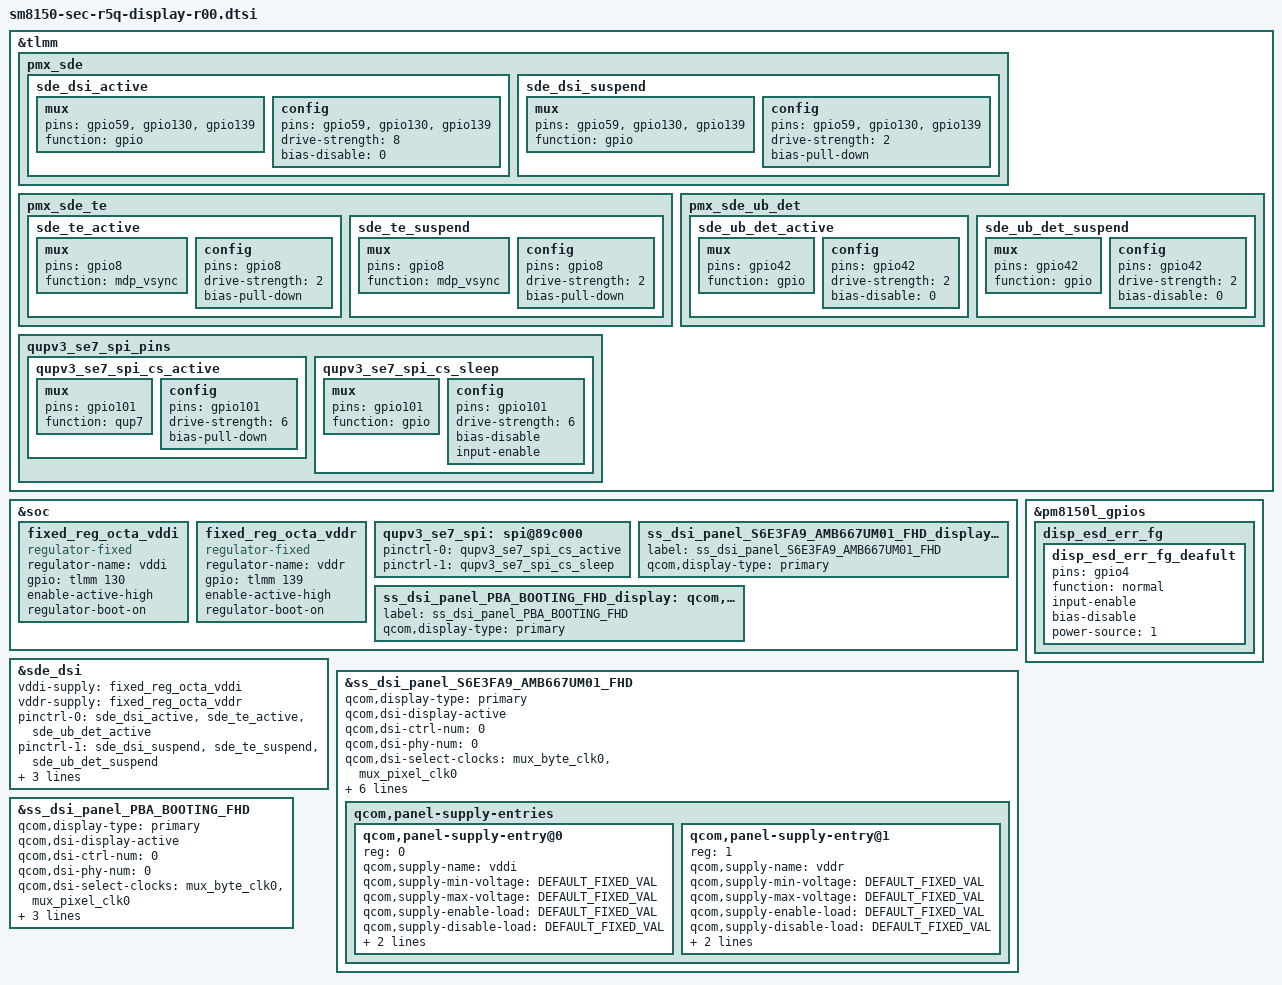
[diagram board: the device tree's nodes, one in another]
/* Copyright (c) 2016-2019, The Linux Foundation. All rights reserved.
 *
 * This program is free software; you can redistribute it and/or modify
 * it under the terms of the GNU General Public License version 2 and
 * only version 2 as published by the Free Software Foundation.
 *
 * This program is distributed in the hope that it will be useful,
 * but WITHOUT ANY WARRANTY; without even the implied warranty of
 * MERCHANTABILITY or FITNESS FOR A PARTICULAR PURPOSE.  See the
 * GNU General Public License for more details.
 */

#include "../../../../../drivers/gpu/drm/msm/samsung/SELF_DISPLAY/self_display_cmd_FA9.dtsi"
#include "../../../../../drivers/gpu/drm/msm/samsung/S6E3FA9_AMB667UM01/dsi_panel_S6E3FA9_AMB667UM01_fhd_octa_cmd.dtsi"
#include "../../../../../drivers/gpu/drm/msm/samsung/PBA_BOOTING/dsi_panel_PBA_BOOTING_fhd_video.dtsi"

#define DEFAULT_FIXED_VAL	0

&tlmm {
	pmx_sde: pmx_sde {
		sde_dsi_active: sde_dsi_active {
			mux {
				pins = "gpio59","gpio130","gpio139";
				function = "gpio";
			};

			config {
				pins = "gpio59","gpio130","gpio139";
				drive-strength = <8>;   /* 8 mA */
				bias-disable = <0>;   /* no pull */
			};
		};
		sde_dsi_suspend: sde_dsi_suspend {
			mux {
				pins = "gpio59","gpio130","gpio139";
				function = "gpio";
			};

			config {
				pins = "gpio59","gpio130","gpio139";
				drive-strength = <2>;   /* 2 mA */
				bias-pull-down;         /* PULL DOWN */
			};
		};
	};

	pmx_sde_te {
		sde_te_active: sde_te_active {
			mux {
				pins = "gpio8";
				function = "mdp_vsync";
			};

			config {
				pins = "gpio8";
				drive-strength = <2>;   /* 2 mA */
				bias-pull-down;         /* PULL DOWN */
			};
		};

		sde_te_suspend: sde_te_suspend {
			mux {
				pins = "gpio8";
				function = "mdp_vsync";
			};

			config {
				pins = "gpio8";
				drive-strength = <2>;   /* 2 mA */
				bias-pull-down;         /* PULL DOWN */
			};
		};
	};

	pmx_sde_ub_det {
		sde_ub_det_active: sde_ub_det_active {	/* UB_CON_DET */
			mux {
				pins = "gpio42";
				function = "gpio";
			};

			config {
				pins = "gpio42";
				drive-strength = <2>;   /* 2 mA */
				bias-disable = <0>;   /* no pull */
			};
		};

		sde_ub_det_suspend: sde_ub_det_suspend {
			mux {
				pins = "gpio42";
				function = "gpio";
			};

			config {
				pins = "gpio42";
				drive-strength = <2>;   /* 2 mA */
				bias-disable = <0>;   /* no pull */
			};
		};
	};

	qupv3_se7_spi_pins: qupv3_se7_spi_pins {
		qupv3_se7_spi_cs_active: qupv3_se7_spi_cs_active {
			mux {
				pins = "gpio101";
				function = "qup7";
			};

			config {
				pins = "gpio101";
				drive-strength = <6>;
				bias-pull-down; /* prevent MISO floating */
			};
		};

		qupv3_se7_spi_cs_sleep: qupv3_se7_spi_cs_sleep {
			mux {
				pins = "gpio101";
				function = "gpio";
			};

			config {
				pins = "gpio101";
				drive-strength = <6>;
				bias-disable;           /* NO PULL */
				input-enable;
			};
		};
	};
};

&soc {
	fixed_reg_octa_vddi: fixed_reg_octa_vddi {
		compatible = "regulator-fixed";
		status = "okay";
		regulator-name = "vddi";
		gpio = <&tlmm 130 0>; /* LCD_LDO_EN : 3.0 & 1.8 V */
		enable-active-high;
		regulator-boot-on;
	};
};

&soc {
	fixed_reg_octa_vddr: fixed_reg_octa_vddr {
		compatible = "regulator-fixed";
		status = "okay";
		regulator-name = "vddr";
		gpio = <&tlmm 139 0>; /* LCD_VDDR_EN : 1.5 V */
		enable-active-high;
		regulator-boot-on;
	};
};

&pm8150l_gpios {
	disp_esd_err_fg {
		disp_esd_err_fg_deafult: disp_esd_err_fg_deafult { // FG_ERR
			pins = "gpio4";
			function = "normal";
			input-enable;
			bias-disable;
			power-source = <1>;
		};
	};
};

&soc {
	qupv3_se7_spi: spi@89c000 {
		status = "ok";

		pinctrl-0 = <&qupv3_se7_spi_cs_active>;
		pinctrl-1 = <&qupv3_se7_spi_cs_sleep>;
	};
};

&soc {
	/* R5 Panel */
	ss_dsi_panel_S6E3FA9_AMB667UM01_FHD_display: qcom,dsi-display@0 {
		label = "ss_dsi_panel_S6E3FA9_AMB667UM01_FHD";
		qcom,display-type = "primary";
	};

	/* PBA */
	ss_dsi_panel_PBA_BOOTING_FHD_display: qcom,dsi-display@1 {
		label = "ss_dsi_panel_PBA_BOOTING_FHD";
		qcom,display-type = "primary";
	};
};

&sde_dsi {
	vddi-supply = <&fixed_reg_octa_vddi>;
	vddr-supply = <&fixed_reg_octa_vddr>;

	pinctrl-names = "panel_active", "panel_suspend";
	pinctrl-0 = <&sde_dsi_active &sde_te_active &sde_ub_det_active>;
	pinctrl-1 = <&sde_dsi_suspend &sde_te_suspend &sde_ub_det_suspend>;

	qcom,dsi-display-list =
		<&ss_dsi_panel_S6E3FA9_AMB667UM01_FHD
		&ss_dsi_panel_PBA_BOOTING_FHD>;
};

&ss_dsi_panel_S6E3FA9_AMB667UM01_FHD {
	qcom,display-type = "primary";
	qcom,dsi-display-active;

	qcom,dsi-ctrl-num = <0>;
	qcom,dsi-phy-num = <0>;
	qcom,dsi-select-clocks = "mux_byte_clk0", "mux_pixel_clk0";

	qcom,dsi-panel = <&ss_dsi_panel_S6E3FA9_AMB667UM01_FHD>;

	qcom,platform-reset-gpio = <&tlmm 59 0>;
	qcom,platform-te-gpio = <&tlmm 8 0>;

	samsung,ub-con-det = <&tlmm 42 0>; // UB_CON_DET
	samsung,support-optical-fingerprint;

	qcom,panel-supply-entries {
		#address-cells = <1>;
		#size-cells = <0>;

		/* use fixed regulator instead of samsung,panel-extra-power-gpio or qcom,platform-enable-gpio. */
		qcom,panel-supply-entry@0 {
			reg = <0>;
			qcom,supply-name = "vddi"; // 3.0V , 1.8V
			qcom,supply-min-voltage = <DEFAULT_FIXED_VAL>;
			qcom,supply-max-voltage = <DEFAULT_FIXED_VAL>;
			qcom,supply-enable-load = <DEFAULT_FIXED_VAL>;
			qcom,supply-disable-load = <DEFAULT_FIXED_VAL>;
			qcom,supply-pre-off-sleep = <0>;
			qcom,supply-post-on-sleep = <0>;
		};
		qcom,panel-supply-entry@1 {
			reg = <1>;
			qcom,supply-name = "vddr"; // 1.5 V
			qcom,supply-min-voltage = <DEFAULT_FIXED_VAL>;
			qcom,supply-max-voltage = <DEFAULT_FIXED_VAL>;
			qcom,supply-enable-load = <DEFAULT_FIXED_VAL>;
			qcom,supply-disable-load = <DEFAULT_FIXED_VAL>;
			qcom,supply-pre-off-sleep = <0>;
			qcom,supply-post-on-sleep = <0>;
		};
	};
};

&ss_dsi_panel_PBA_BOOTING_FHD {
	qcom,display-type = "primary";
	qcom,dsi-display-active;

	qcom,dsi-ctrl-num = <0>;
	qcom,dsi-phy-num = <0>;
	qcom,dsi-select-clocks = "mux_byte_clk0", "mux_pixel_clk0";

	qcom,dsi-panel = <&ss_dsi_panel_PBA_BOOTING_FHD>;

	qcom,platform-reset-gpio = <&tlmm 59 0>;
	qcom,platform-te-gpio = <&tlmm 8 0>;
};
